VERSION ""

NS_ :

BS_:

BU_: Air_control
VAL_TABLE_ REC 1 "ON" 0 "OFF" ;
VAL_TABLE_ AC 1 "ON" 0 "OFF" ;
VAL_TABLE_ Display 1 "ON" 0 "OFF" ;
VAL_TABLE_ Seletor_de_Direcao 3 "Frente(Rosto)" 2 "desembassador" 1 "pes_desembassador" 0 "pes" ;
VAL_TABLE_ Seletor_de_Velocidade 4 "4" 3 "3" 2 "2" 1 "1" 0 "0" ;

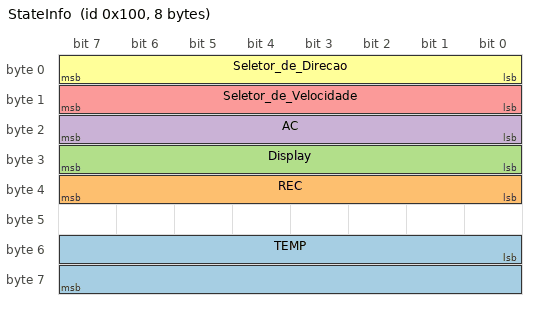
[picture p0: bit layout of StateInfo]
BO_ 256 StateInfo: 8 Air_control
 SG_ TEMP : 48|16@1- (1,0) [0|100] "°C" Vector__XXX
 SG_ REC : 32|8@1- (1,0) [0|1] "" Vector__XXX
 SG_ Display : 24|8@1+ (1,0) [0|1] "" Vector__XXX
 SG_ AC : 16|8@1- (1,0) [0|1] "" Vector__XXX
 SG_ Seletor_de_Velocidade : 8|8@1+ (0.25,0) [0|4] ""  Air_control
 SG_ Seletor_de_Direcao : 0|8@1+ (1,0) [0|4] ""  Air_control

BA_DEF_  "BusType" STRING ;
BA_DEF_DEF_  "BusType" "CAN";
VAL_ 256 REC 1 "ON" 0 "OFF" ;
VAL_ 256 Display 1 "ON" 0 "OFF" ;
VAL_ 256 AC 1 "ON" 0 "OFF" ;
VAL_ 256 Seletor_de_Velocidade 4 "4" 3 "3" 2 "2" 1 "1" 0 "0" ;
VAL_ 256 Seletor_de_Direcao 3 "Frente(Rosto)" 2 "desembassador" 1 "pes_desembassador" 0 "pes" ;
